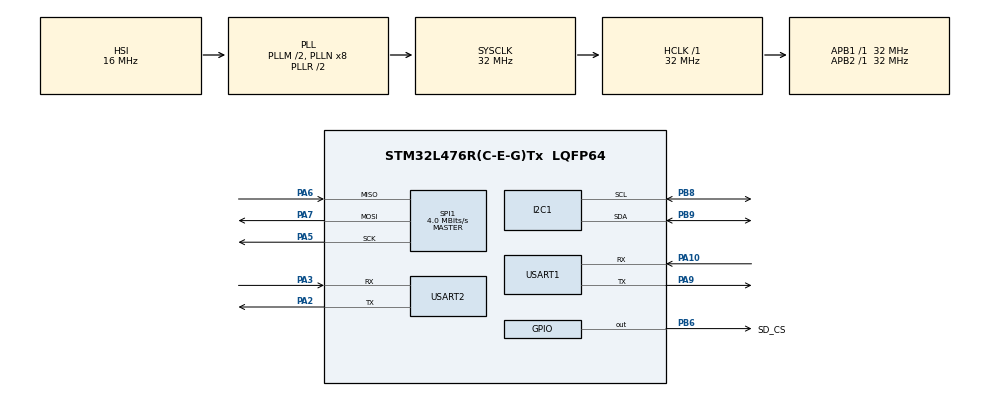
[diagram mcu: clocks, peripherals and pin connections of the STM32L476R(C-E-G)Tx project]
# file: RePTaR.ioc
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Mcu.Family=STM32L4
PA6.Mode=Full_Duplex_Master
RCC.CortexFreq_Value=32000000
FATFS._USE_LFN=1
SPI1.VirtualType=VM_MASTER
PH0-OSC_IN\ (PH0).Signal=RCC_OSC_IN
VP_RTC_VS_RTC_Activate.Mode=RTC_Enabled
RTC.WeekDay=RTC_WEEKDAY_FRIDAY
PB6.GPIO_Label=SD_CS
PC15-OSC32_OUT\ (PC15).Mode=LSE-External-Oscillator
RCC.SYSCLKSource=RCC_SYSCLKSOURCE_PLLCLK
ProjectManager.StackSize=0x400
PC14-OSC32_IN\ (PC14).Mode=LSE-External-Oscillator
SPI1.Direction=SPI_DIRECTION_2LINES
RCC.HCLKFreq_Value=32000000
RCC.APB2TimFreq_Value=32000000
PB6.Signal=GPIO_Output
SPI1.CalculateBaudRate=4.0 MBits/s
RCC.AHBFreq_Value=32000000
PH1-OSC_OUT\ (PH1).Mode=HSE-External-Oscillator
RCC.HSE_VALUE=8000000
RTC.Minutes=27
USART2.VirtualMode-Asynchronous=VM_ASYNC
RCC.RTCClockSelection=RCC_RTCCLKSOURCE_LSE
PA6.GPIO_PuPd=GPIO_NOPULL
RTC.Month=RTC_MONTH_MARCH
PA5.GPIO_PuPd=GPIO_NOPULL
SPI1.DataSize=SPI_DATASIZE_8BIT
Mcu.Package=LQFP64
PB9.Signal=I2C1_SDA
PA6.Signal=SPI1_MISO
PA10.Signal=USART1_RX
VP_RTC_VS_RTC_Calendar.Mode=RTC_Calendar
RCC.APB1TimFreq_Value=32000000
SPI1.BaudRatePrescaler=SPI_BAUDRATEPRESCALER_8
PH0-OSC_IN\ (PH0).Mode=HSE-External-Oscillator
PB9.GPIO_FM9=__NULL
PA3.Signal=USART2_RX
PA5.Mode=Full_Duplex_Master
RCC.MSI_VALUE=4000000
RCC.PLLSourceVirtual=RCC_PLLSOURCE_HSI
PA7.Mode=Full_Duplex_Master
PA10.Mode=Asynchronous
PB8.GPIO_FM8=__NULL
PB6.GPIO_PuPd=GPIO_NOPULL
PC15-OSC32_OUT\ (PC15).Signal=RCC_OSC32_OUT
PH1-OSC_OUT\ (PH1).Signal=RCC_OSC_OUT
USART1.VirtualMode-Asynchronous=VM_ASYNC
PA3.Mode=Asynchronous
PA9.Mode=Asynchronous
ProjectManager.TargetToolchain=STM32CubeIDE
RTC.Year=21
PB9.Mode=I2C
PA9.Signal=USART1_TX
I2C1.Timing=0x00707CBB
RCC.USBFreq_Value=32000000
PA7.GPIO_PuPd=GPIO_NOPULL
VP_FATFS_VS_Generic.Mode=User_defined
PA5.Signal=SPI1_SCK
board=custom
RCC.VCOOutputFreq_Value=64000000
RCC.APB2Freq_Value=32000000
SPI1.Mode=SPI_MODE_MASTER
RCC.ADCFreq_Value=32000000
Mcu.Name=STM32L476R(C-E-G)Tx
PA2.Signal=USART2_TX
FATFS._MAX_SS=4096
RCC.SYSCLKFreq_VALUE=32000000
RTC.Hours=14
PC14-OSC32_IN\ (PC14).Signal=RCC_OSC32_IN
PB6.PinState=GPIO_PIN_SET
RTC.HourFormat=RTC_HOURFORMAT_24
ProjectManager.HeapSize=0x200
RCC.HSI_VALUE=16000000
NVIC.PriorityGroup=NVIC_PRIORITYGROUP_4
RCC.PLLM=2
PB8.Mode=I2C
PA2.Mode=Asynchronous
PB8.Signal=I2C1_SCL
PB6.GPIO_Speed=GPIO_SPEED_FREQ_MEDIUM
RCC.APB1Freq_Value=32000000
RTC.Date=26
PA7.Signal=SPI1_MOSI

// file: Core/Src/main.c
/* USER CODE BEGIN Header */
/**
  ******************************************************************************
  * @file           : main.c
  * @brief          : Main program body
  ******************************************************************************
  * @attention
  *
  * <h2><center>&copy; Copyright (c) 2021 STMicroelectronics.
  * All rights reserved.</center></h2>
  *
  * This software component is licensed by ST under BSD 3-Clause license,
  * the "License"; You may not use this file except in compliance with the
  * License. You may obtain a copy of the License at:
  *                        opensource.org/licenses/BSD-3-Clause
  *
  ******************************************************************************
  */
/* USER CODE END Header */
#include "main.h"
#include "fatfs.h"

/* USER CODE BEGIN Includes */
#include "reptar_main.h"
/* USER CODE END Includes */

I2C_HandleTypeDef hi2c1;

RTC_HandleTypeDef hrtc;

SPI_HandleTypeDef hspi1;

UART_HandleTypeDef huart1;
UART_HandleTypeDef huart2;

void SystemClock_Config(void);
static void MX_GPIO_Init(void);
static void MX_I2C1_Init(void);
static void MX_SPI1_Init(void);
static void MX_USART2_UART_Init(void);
static void MX_USART1_UART_Init(void);
static void MX_RTC_Init(void);

int main(void)
{
  /* USER CODE BEGIN 1 */
  error_code_t retval = E_OK;
  /* USER CODE END 1 */

  /* MCU Configuration--------------------------------------------------------*/

  /* Reset of all peripherals, Initializes the Flash interface and the Systick. */
  HAL_Init();

  /* Configure the system clock */
  SystemClock_Config();

  /* Initialize all configured peripherals */
  MX_GPIO_Init();
  MX_I2C1_Init();
  MX_SPI1_Init();
  MX_USART2_UART_Init();
  MX_USART1_UART_Init();
  MX_RTC_Init();
  MX_FATFS_Init();
  /* USER CODE BEGIN 2 */

  retval = reptar_init();

  if (retval != E_OK)
  {
	  while(1);
  }

  /* USER CODE END 2 */

  /* Infinite loop */
  while (1)
  {

  }
}

void SystemClock_Config(void)
{
  RCC_OscInitTypeDef RCC_OscInitStruct = {0};
  RCC_ClkInitTypeDef RCC_ClkInitStruct = {0};
  RCC_PeriphCLKInitTypeDef PeriphClkInit = {0};

  /** Configure LSE Drive Capability
  */
  HAL_PWR_EnableBkUpAccess();
  __HAL_RCC_LSEDRIVE_CONFIG(RCC_LSEDRIVE_LOW);
  /** Initializes the RCC Oscillators according to the specified parameters
  * in the RCC_OscInitTypeDef structure.
  */
  RCC_OscInitStruct.OscillatorType = RCC_OSCILLATORTYPE_HSI|RCC_OSCILLATORTYPE_LSE;
  RCC_OscInitStruct.LSEState = RCC_LSE_ON;
  RCC_OscInitStruct.HSIState = RCC_HSI_ON;
  RCC_OscInitStruct.HSICalibrationValue = RCC_HSICALIBRATION_DEFAULT;
  RCC_OscInitStruct.PLL.PLLState = RCC_PLL_ON;
  RCC_OscInitStruct.PLL.PLLSource = RCC_PLLSOURCE_HSI;
  RCC_OscInitStruct.PLL.PLLM = 2;
  RCC_OscInitStruct.PLL.PLLN = 8;
  RCC_OscInitStruct.PLL.PLLP = RCC_PLLP_DIV7;
  RCC_OscInitStruct.PLL.PLLQ = RCC_PLLQ_DIV2;
  RCC_OscInitStruct.PLL.PLLR = RCC_PLLR_DIV2;
  if (HAL_RCC_OscConfig(&RCC_OscInitStruct) != HAL_OK)
  {
    Error_Handler();
  }
  /** Initializes the CPU, AHB and APB buses clocks
  */
  RCC_ClkInitStruct.ClockType = RCC_CLOCKTYPE_HCLK|RCC_CLOCKTYPE_SYSCLK
                              |RCC_CLOCKTYPE_PCLK1|RCC_CLOCKTYPE_PCLK2;
  RCC_ClkInitStruct.SYSCLKSource = RCC_SYSCLKSOURCE_PLLCLK;
  RCC_ClkInitStruct.AHBCLKDivider = RCC_SYSCLK_DIV1;
  RCC_ClkInitStruct.APB1CLKDivider = RCC_HCLK_DIV1;
  RCC_ClkInitStruct.APB2CLKDivider = RCC_HCLK_DIV1;

  if (HAL_RCC_ClockConfig(&RCC_ClkInitStruct, FLASH_LATENCY_1) != HAL_OK)
  {
    Error_Handler();
  }
  PeriphClkInit.PeriphClockSelection = RCC_PERIPHCLK_RTC|RCC_PERIPHCLK_USART1
                              |RCC_PERIPHCLK_USART2|RCC_PERIPHCLK_I2C1;
  PeriphClkInit.Usart1ClockSelection = RCC_USART1CLKSOURCE_PCLK2;
  PeriphClkInit.Usart2ClockSelection = RCC_USART2CLKSOURCE_PCLK1;
  PeriphClkInit.I2c1ClockSelection = RCC_I2C1CLKSOURCE_PCLK1;
  PeriphClkInit.RTCClockSelection = RCC_RTCCLKSOURCE_LSE;
  if (HAL_RCCEx_PeriphCLKConfig(&PeriphClkInit) != HAL_OK)
  {
    Error_Handler();
  }
  /** Configure the main internal regulator output voltage
  */
  if (HAL_PWREx_ControlVoltageScaling(PWR_REGULATOR_VOLTAGE_SCALE1) != HAL_OK)
  {
    Error_Handler();
  }
}

static void MX_I2C1_Init(void)
{

  hi2c1.Instance = I2C1;
  hi2c1.Init.Timing = 0x00707CBB;
  hi2c1.Init.OwnAddress1 = 0;
  hi2c1.Init.AddressingMode = I2C_ADDRESSINGMODE_7BIT;
  hi2c1.Init.DualAddressMode = I2C_DUALADDRESS_DISABLE;
  hi2c1.Init.OwnAddress2 = 0;
  hi2c1.Init.OwnAddress2Masks = I2C_OA2_NOMASK;
  hi2c1.Init.GeneralCallMode = I2C_GENERALCALL_DISABLE;
  hi2c1.Init.NoStretchMode = I2C_NOSTRETCH_DISABLE;
  if (HAL_I2C_Init(&hi2c1) != HAL_OK)
  {
    Error_Handler();
  }
  /** Configure Analogue filter
  */
  if (HAL_I2CEx_ConfigAnalogFilter(&hi2c1, I2C_ANALOGFILTER_ENABLE) != HAL_OK)
  {
    Error_Handler();
  }
  /** Configure Digital filter
  */
  if (HAL_I2CEx_ConfigDigitalFilter(&hi2c1, 0) != HAL_OK)
  {
    Error_Handler();
  }

}

static void MX_RTC_Init(void)
{

  RTC_TimeTypeDef sTime = {0};
  RTC_DateTypeDef sDate = {0};

  /** Initialize RTC Only
  */
  hrtc.Instance = RTC;
  hrtc.Init.HourFormat = RTC_HOURFORMAT_24;
  hrtc.Init.AsynchPrediv = 127;
  hrtc.Init.SynchPrediv = 255;
  hrtc.Init.OutPut = RTC_OUTPUT_DISABLE;
  hrtc.Init.OutPutRemap = RTC_OUTPUT_REMAP_NONE;
  hrtc.Init.OutPutPolarity = RTC_OUTPUT_POLARITY_HIGH;
  hrtc.Init.OutPutType = RTC_OUTPUT_TYPE_OPENDRAIN;
  if (HAL_RTC_Init(&hrtc) != HAL_OK)
  {
    Error_Handler();
  }

  /* USER CODE BEGIN Check_RTC_BKUP */
  if (HAL_RTCEx_BKUPRead(&hrtc, RTC_BKP_DR0) != RTC_BACKUP_MAGIC_NUM)
  {
	  reptar_printf("Setting up RTC!\r\n");
  /* USER CODE END Check_RTC_BKUP */

  /** Initialize RTC and set the Time and Date
  */
  sTime.Hours = 0x14;
  sTime.Minutes = 0x27;
  sTime.Seconds = 0x0;
  sTime.DayLightSaving = RTC_DAYLIGHTSAVING_NONE;
  sTime.StoreOperation = RTC_STOREOPERATION_RESET;
  if (HAL_RTC_SetTime(&hrtc, &sTime, RTC_FORMAT_BCD) != HAL_OK)
  {
    Error_Handler();
  }
  sDate.WeekDay = RTC_WEEKDAY_FRIDAY;
  sDate.Month = RTC_MONTH_MARCH;
  sDate.Date = 0x26;
  sDate.Year = 0x21;

  if (HAL_RTC_SetDate(&hrtc, &sDate, RTC_FORMAT_BCD) != HAL_OK)
  {
    Error_Handler();
  }
  /* USER CODE BEGIN RTC_Init 2 */
  	  HAL_RTCEx_BKUPWrite(&hrtc, RTC_BKP_DR0, RTC_BACKUP_MAGIC_NUM);
  }
  /* USER CODE END RTC_Init 2 */

}

static void MX_SPI1_Init(void)
{

  /* SPI1 parameter configuration*/
  hspi1.Instance = SPI1;
  hspi1.Init.Mode = SPI_MODE_MASTER;
  hspi1.Init.Direction = SPI_DIRECTION_2LINES;
  hspi1.Init.DataSize = SPI_DATASIZE_8BIT;
  hspi1.Init.CLKPolarity = SPI_POLARITY_LOW;
  hspi1.Init.CLKPhase = SPI_PHASE_1EDGE;
  hspi1.Init.NSS = SPI_NSS_SOFT;
  hspi1.Init.BaudRatePrescaler = SPI_BAUDRATEPRESCALER_8;
  hspi1.Init.FirstBit = SPI_FIRSTBIT_MSB;
  hspi1.Init.TIMode = SPI_TIMODE_DISABLE;
  hspi1.Init.CRCCalculation = SPI_CRCCALCULATION_DISABLE;
  hspi1.Init.CRCPolynomial = 7;
  hspi1.Init.CRCLength = SPI_CRC_LENGTH_DATASIZE;
  hspi1.Init.NSSPMode = SPI_NSS_PULSE_ENABLE;
  if (HAL_SPI_Init(&hspi1) != HAL_OK)
  {
    Error_Handler();
  }

}

static void MX_USART1_UART_Init(void)
{

  huart1.Instance = USART1;
  huart1.Init.BaudRate = 115200;
  huart1.Init.WordLength = UART_WORDLENGTH_8B;
  huart1.Init.StopBits = UART_STOPBITS_1;
  huart1.Init.Parity = UART_PARITY_NONE;
  huart1.Init.Mode = UART_MODE_TX_RX;
  huart1.Init.HwFlowCtl = UART_HWCONTROL_NONE;
  huart1.Init.OverSampling = UART_OVERSAMPLING_16;
  huart1.Init.OneBitSampling = UART_ONE_BIT_SAMPLE_DISABLE;
  huart1.AdvancedInit.AdvFeatureInit = UART_ADVFEATURE_NO_INIT;
  if (HAL_UART_Init(&huart1) != HAL_OK)
  {
    Error_Handler();
  }

}

static void MX_USART2_UART_Init(void)
{

  huart2.Instance = USART2;
  huart2.Init.BaudRate = 115200;
  huart2.Init.WordLength = UART_WORDLENGTH_8B;
  huart2.Init.StopBits = UART_STOPBITS_1;
  huart2.Init.Parity = UART_PARITY_NONE;
  huart2.Init.Mode = UART_MODE_TX_RX;
  huart2.Init.HwFlowCtl = UART_HWCONTROL_NONE;
  huart2.Init.OverSampling = UART_OVERSAMPLING_16;
  huart2.Init.OneBitSampling = UART_ONE_BIT_SAMPLE_DISABLE;
  huart2.AdvancedInit.AdvFeatureInit = UART_ADVFEATURE_NO_INIT;
  if (HAL_UART_Init(&huart2) != HAL_OK)
  {
    Error_Handler();
  }

}

static void MX_GPIO_Init(void)
{
  GPIO_InitTypeDef GPIO_InitStruct = {0};

  /* GPIO Ports Clock Enable */
  __HAL_RCC_GPIOC_CLK_ENABLE();
  __HAL_RCC_GPIOH_CLK_ENABLE();
  __HAL_RCC_GPIOA_CLK_ENABLE();
  __HAL_RCC_GPIOB_CLK_ENABLE();

  /*Configure GPIO pin Output Level */
  HAL_GPIO_WritePin(SD_CS_GPIO_Port, SD_CS_Pin, GPIO_PIN_SET);

  /*Configure GPIO pin : SD_CS_Pin */
  GPIO_InitStruct.Pin = SD_CS_Pin;
  GPIO_InitStruct.Mode = GPIO_MODE_OUTPUT_PP;
  GPIO_InitStruct.Pull = GPIO_NOPULL;
  GPIO_InitStruct.Speed = GPIO_SPEED_FREQ_MEDIUM;
  HAL_GPIO_Init(SD_CS_GPIO_Port, &GPIO_InitStruct);

}

void Error_Handler(void)
{
  __disable_irq();
  while (1)
  {
  }
}

/************************ (C) COPYRIGHT STMicroelectronics *****END OF FILE****/
